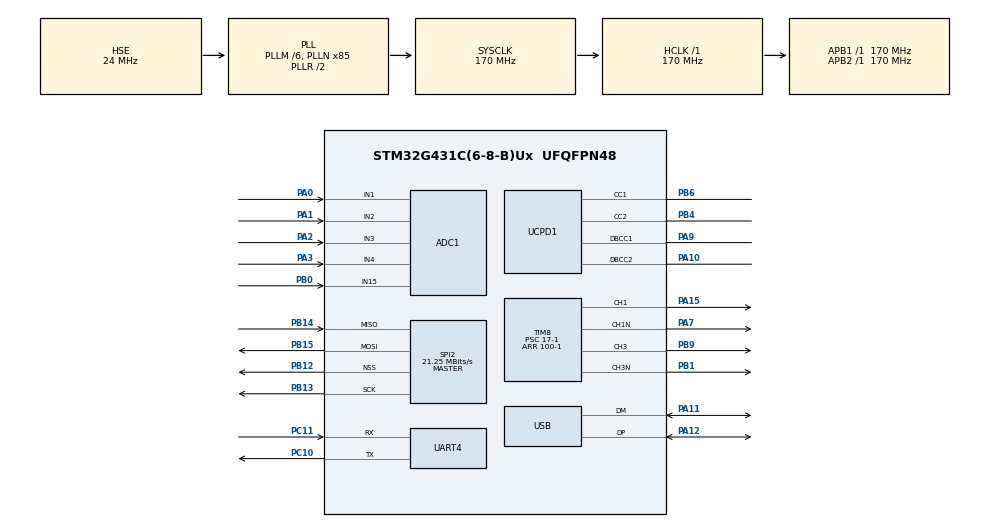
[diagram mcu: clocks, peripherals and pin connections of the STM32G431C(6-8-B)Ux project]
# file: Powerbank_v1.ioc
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ADC1.Channel-0\#ChannelRegularConversion=ADC_CHANNEL_1
ADC1.Channel-1\#ChannelRegularConversion=ADC_CHANNEL_2
ADC1.Channel-2\#ChannelRegularConversion=ADC_CHANNEL_3
ADC1.Channel-3\#ChannelRegularConversion=ADC_CHANNEL_4
ADC1.Channel-4\#ChannelRegularConversion=ADC_CHANNEL_15
ADC1.ContinuousConvMode=ENABLE
ADC1.DMAContinuousRequests=ENABLE
ADC1.DiscontinuousConvMode=DISABLE
ADC1.ExternalTrigConv=ADC_EXTERNALTRIG_T3_TRGO
ADC1.NbrOfConversion=5
ADC1.NbrOfConversionFlag=1
ADC1.OffsetNumber-0\#ChannelRegularConversion=ADC_OFFSET_NONE
ADC1.OffsetNumber-1\#ChannelRegularConversion=ADC_OFFSET_NONE
ADC1.OffsetNumber-2\#ChannelRegularConversion=ADC_OFFSET_NONE
ADC1.OffsetNumber-3\#ChannelRegularConversion=ADC_OFFSET_NONE
ADC1.OffsetNumber-4\#ChannelRegularConversion=ADC_OFFSET_NONE
ADC1.Overrun=ADC_OVR_DATA_OVERWRITTEN
ADC1.Rank-0\#ChannelRegularConversion=1
ADC1.Rank-1\#ChannelRegularConversion=2
ADC1.Rank-2\#ChannelRegularConversion=3
ADC1.Rank-3\#ChannelRegularConversion=4
ADC1.Rank-4\#ChannelRegularConversion=5
ADC1.SamplingTime-0\#ChannelRegularConversion=ADC_SAMPLETIME_640CYCLES_5
ADC1.SamplingTime-1\#ChannelRegularConversion=ADC_SAMPLETIME_640CYCLES_5
ADC1.SamplingTime-2\#ChannelRegularConversion=ADC_SAMPLETIME_640CYCLES_5
ADC1.SamplingTime-3\#ChannelRegularConversion=ADC_SAMPLETIME_640CYCLES_5
ADC1.SamplingTime-4\#ChannelRegularConversion=ADC_SAMPLETIME_640CYCLES_5
ADC1.master=1
Dma.ADC1.2.Direction=DMA_PERIPH_TO_MEMORY
Dma.ADC1.2.EventEnable=DISABLE
Dma.ADC1.2.Instance=DMA1_Channel3
Dma.ADC1.2.MemDataAlignment=DMA_MDATAALIGN_WORD
Dma.ADC1.2.MemInc=DMA_MINC_ENABLE
Dma.ADC1.2.Mode=DMA_CIRCULAR
Dma.ADC1.2.PeriphDataAlignment=DMA_PDATAALIGN_HALFWORD
Dma.ADC1.2.PeriphInc=DMA_PINC_DISABLE
Dma.ADC1.2.Polarity=HAL_DMAMUX_REQ_GEN_RISING
Dma.ADC1.2.Priority=DMA_PRIORITY_HIGH
Dma.ADC1.2.RequestNumber=1
Dma.ADC1.2.SignalID=NONE
Dma.ADC1.2.SyncEnable=DISABLE
Dma.ADC1.2.SyncPolarity=HAL_DMAMUX_SYNC_NO_EVENT
Dma.ADC1.2.SyncRequestNumber=1
Dma.ADC1.2.SyncSignalID=NONE
Dma.Request0=UCPD1_RX
Dma.Request1=UCPD1_TX
Dma.Request2=ADC1
Dma.UCPD1_RX.0.Direction=DMA_PERIPH_TO_MEMORY
Dma.UCPD1_RX.0.EventEnable=DISABLE
Dma.UCPD1_RX.0.Instance=DMA1_Channel1
Dma.UCPD1_RX.0.MemDataAlignment=DMA_MDATAALIGN_BYTE
Dma.UCPD1_RX.0.MemInc=DMA_MINC_ENABLE
Dma.UCPD1_RX.0.Mode=DMA_NORMAL
Dma.UCPD1_RX.0.PeriphDataAlignment=DMA_PDATAALIGN_BYTE
Dma.UCPD1_RX.0.PeriphInc=DMA_PINC_DISABLE
Dma.UCPD1_RX.0.Polarity=HAL_DMAMUX_REQ_GEN_RISING
Dma.UCPD1_RX.0.Priority=DMA_PRIORITY_LOW
Dma.UCPD1_RX.0.RequestNumber=1
Dma.UCPD1_RX.0.SignalID=NONE
Dma.UCPD1_RX.0.SyncEnable=DISABLE
Dma.UCPD1_RX.0.SyncPolarity=HAL_DMAMUX_SYNC_NO_EVENT
Dma.UCPD1_RX.0.SyncRequestNumber=1
Dma.UCPD1_RX.0.SyncSignalID=NONE
Dma.UCPD1_TX.1.Direction=DMA_MEMORY_TO_PERIPH
Dma.UCPD1_TX.1.EventEnable=DISABLE
Dma.UCPD1_TX.1.Instance=DMA1_Channel2
Dma.UCPD1_TX.1.MemDataAlignment=DMA_MDATAALIGN_BYTE
Dma.UCPD1_TX.1.MemInc=DMA_MINC_ENABLE
Dma.UCPD1_TX.1.Mode=DMA_NORMAL
Dma.UCPD1_TX.1.PeriphDataAlignment=DMA_PDATAALIGN_BYTE
Dma.UCPD1_TX.1.PeriphInc=DMA_PINC_DISABLE
Dma.UCPD1_TX.1.Polarity=HAL_DMAMUX_REQ_GEN_RISING
Dma.UCPD1_TX.1.Priority=DMA_PRIORITY_LOW
Dma.UCPD1_TX.1.RequestNumber=1
Dma.UCPD1_TX.1.SignalID=NONE
Dma.UCPD1_TX.1.SyncEnable=DISABLE
Dma.UCPD1_TX.1.SyncPolarity=HAL_DMAMUX_SYNC_NO_EVENT
Dma.UCPD1_TX.1.SyncRequestNumber=1
Dma.UCPD1_TX.1.SyncSignalID=NONE
FREERTOS.Tasks01=defaultTask,24,512,StartDefaultTask,Default,NULL,Dynamic,NULL,NULL
FREERTOS.configMINIMAL_STACK_SIZE=512
FREERTOS.configTOTAL_HEAP_SIZE=8000
FREERTOS.configUSE_NEWLIB_REENTRANT=1
Mcu.Family=STM32G4
Mcu.Name=STM32G431C(6-8-B)Ux
Mcu.Package=UFQFPN48
Mcu.UserConstants=VDDA_APPLI,3300
NVIC.DMA1_Channel1_IRQn=true\:5\:0\:false\:false\:true\:true\:false\:true\:true
NVIC.DMA1_Channel2_IRQn=true\:5\:0\:false\:false\:true\:true\:false\:true\:true
NVIC.DMA1_Channel3_IRQn=true\:5\:0\:false\:false\:true\:true\:false\:true\:true
NVIC.PriorityGroup=NVIC_PRIORITYGROUP_4
NVIC.TIM1_TRG_COM_TIM17_IRQn=true\:5\:0\:false\:false\:true\:false\:false\:true\:true
NVIC.TimeBase=TIM1_TRG_COM_TIM17_IRQn
NVIC.TimeBaseIP=TIM17
NVIC.UCPD1_IRQn=true\:5\:0\:false\:false\:true\:true\:true\:false\:true
NVIC.USB_LP_IRQn=true\:5\:0\:false\:false\:true\:true\:false\:true\:true
PA0.Mode=IN1-Single-Ended
PA0.Signal=ADC1_IN1
PA1.Mode=IN2-Single-Ended
PA1.Signal=ADC1_IN2
PA10.Mode=EnableDeadBattery
PA10.Signal=UCPD1_DBCC2
PA11.Mode=Device
PA11.Signal=USB_DM
PA12.Mode=Device
PA12.Signal=USB_DP
PA15.Signal=S_TIM8_CH1
PA2.Mode=IN3-Single-Ended
PA2.Signal=ADC1_IN3
PA3.Mode=IN4-Single-Ended
PA3.Signal=ADC1_IN4
PA7.Mode=PWM Generation1 CH1 CH1N
PA7.Signal=TIM8_CH1N
PA9.Mode=EnableDeadBattery
PA9.Signal=UCPD1_DBCC1
PB0.Mode=IN15-Single-Ended
PB0.Signal=ADC1_IN15
PB1.Mode=PWM Generation3 CH3 CH3N
PB1.Signal=TIM8_CH3N
PB12.Mode=NSS_Signal_Hard_Output
PB12.Signal=SPI2_NSS
PB13.Mode=Full_Duplex_Master
PB13.Signal=SPI2_SCK
PB14.Mode=Full_Duplex_Master
PB14.Signal=SPI2_MISO
PB15.Mode=Full_Duplex_Master
PB15.Signal=SPI2_MOSI
PB4.Mode=Dual_Role_AllSignals
PB4.Signal=UCPD1_CC2
PB6.Mode=Dual_Role_AllSignals
PB6.Signal=UCPD1_CC1
PB9.Signal=S_TIM8_CH3
PC10.Mode=Asynchronous
PC10.Signal=UART4_TX
PC11.Mode=Asynchronous
PC11.Signal=UART4_RX
PC14-OSC32_IN.Mode=LSE-External-Oscillator
PC14-OSC32_IN.Signal=RCC_OSC32_IN
PC15-OSC32_OUT.Mode=LSE-External-Oscillator
PC15-OSC32_OUT.Signal=RCC_OSC32_OUT
PF0-OSC_IN.Mode=HSE-External-Oscillator
PF0-OSC_IN.Signal=RCC_OSC_IN
PF1-OSC_OUT.Mode=HSE-External-Oscillator
PF1-OSC_OUT.Signal=RCC_OSC_OUT
ProjectManager.HeapSize=0x200
ProjectManager.StackSize=0x400
ProjectManager.TargetToolchain=STM32CubeIDE
RCC.ADC12Freq_Value=170000000
RCC.AHBFreq_Value=170000000
RCC.APB1Freq_Value=170000000
RCC.APB1TimFreq_Value=170000000
RCC.APB2Freq_Value=170000000
RCC.APB2TimFreq_Value=170000000
RCC.CK48CLockSelection=RCC_USBCLKSOURCE_HSI48
RCC.CortexFreq_Value=170000000
RCC.EXTERNAL_CLOCK_VALUE=12288000
RCC.HCLKFreq_Value=170000000
RCC.HSE_VALUE=24000000
RCC.HSI48_VALUE=48000000
RCC.HSI_VALUE=16000000
RCC.PLLM=RCC_PLLM_DIV6
RCC.PLLN=85
RCC.PLLSourceVirtual=RCC_PLLSOURCE_HSE
RCC.SYSCLKFreq_VALUE=170000000
RCC.SYSCLKSource=RCC_SYSCLKSOURCE_PLLCLK
RCC.USBFreq_Value=48000000
RCC.VCOOutputFreq_Value=340000000
SH.S_TIM8_CH1.0=TIM8_CH1,PWM Generation1 CH1 CH1N
SH.S_TIM8_CH3.0=TIM8_CH3,PWM Generation3 CH3 CH3N
SPI2.BaudRatePrescaler=SPI_BAUDRATEPRESCALER_8
SPI2.CalculateBaudRate=21.25 MBits/s
SPI2.Direction=SPI_DIRECTION_2LINES
SPI2.Mode=SPI_MODE_MASTER
SPI2.VirtualNSS=VM_NSSHARD
SPI2.VirtualType=VM_MASTER
TIM3.PeriodNoDither=100-1
TIM3.Prescaler=17-1
TIM3.TIM_MasterOutputTrigger=TIM_TRGO_UPDATE
TIM8.Channel-PWM\ Generation1\ CH1\ CH1N=TIM_CHANNEL_1
TIM8.Channel-PWM\ Generation3\ CH3\ CH3N=TIM_CHANNEL_3
TIM8.PeriodNoDither=100-1
TIM8.Prescaler=17-1
USB_DEVICE.CLASS_NAME_FS=CDC
USB_DEVICE.VirtualMode=Cdc
USB_DEVICE.VirtualModeFS=Cdc_FS
VP_FREERTOS_VS_CMSIS_V2.Mode=CMSIS_V2
VP_SYS_VS_DBSignals.Mode=DisableDeadBatterySignals
VP_SYS_VS_tim17.Mode=TIM17
VP_TIM3_VS_ClockSourceINT.Mode=Internal
VP_USB_DEVICE_VS_USB_DEVICE_CDC_FS.Mode=CDC_FS
board=custom

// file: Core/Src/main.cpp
/* USER CODE BEGIN Header */
/**
  ******************************************************************************
  * @file           : main.c
  * @brief          : Main program body
  ******************************************************************************
  * @attention
  *
  * Copyright (c) 2025 STMicroelectronics.
  * All rights reserved.
  *
  * This software is licensed under terms that can be found in the LICENSE file
  * in the root directory of this software component.
  * If no LICENSE file comes with this software, it is provided AS-IS.
  *
  ******************************************************************************
  */
/* USER CODE END Header */
#include "main.h"
#include "cmsis_os.h"
#include "usb_device.h"

/* USER CODE BEGIN Includes */
#include "Statemachine.h"

/* USER CODE END Includes */

ADC_HandleTypeDef hadc1;
DMA_HandleTypeDef hdma_adc1;

SPI_HandleTypeDef hspi2;

TIM_HandleTypeDef htim3;
TIM_HandleTypeDef htim8;

UART_HandleTypeDef huart4;

/* Definitions for defaultTask */
osThreadId_t defaultTaskHandle;
const osThreadAttr_t defaultTask_attributes = {
  .name = "defaultTask",
  .stack_size = 512 * 4,
  .priority = (osPriority_t) osPriorityNormal
};
/* USER CODE BEGIN PV */
//USBPD_StatusTypeDef status;

Statemachine statemachine(&huart4, &hadc1, &htim3, &htim8, &hspi2);

extern "C" void SystemClock_Config(void);
/* USER CODE END PV */

void SystemClock_Config(void);
static void MX_GPIO_Init(void);
static void MX_DMA_Init(void);
static void MX_UCPD1_Init(void);
static void MX_UART4_Init(void);
static void MX_TIM8_Init(void);
static void MX_ADC1_Init(void);
static void MX_TIM3_Init(void);
static void MX_SPI2_Init(void);
void StartDefaultTask(void *argument);

int main(void)
{

  /* MCU Configuration--------------------------------------------------------*/

  /* Reset of all peripherals, Initializes the Flash interface and the Systick. */
  HAL_Init();

  /* Configure the system clock */
  SystemClock_Config();

  /* Initialize all configured peripherals */
  MX_GPIO_Init();
  MX_DMA_Init();
  MX_UCPD1_Init();
  MX_UART4_Init();
  MX_TIM8_Init();
  MX_ADC1_Init();
  MX_TIM3_Init();
  MX_SPI2_Init();

  /* Init scheduler */
  osKernelInitialize();

  /* Create the thread(s) */
  /* creation of defaultTask */
  defaultTaskHandle = osThreadNew(StartDefaultTask, NULL, &defaultTask_attributes);

  /* Start scheduler */
  osKernelStart();

  /* We should never get here as control is now taken by the scheduler */

  /* Infinite loop */
  while (1)
  {

  }
}

void SystemClock_Config(void)
{
  RCC_OscInitTypeDef RCC_OscInitStruct = {0};
  RCC_ClkInitTypeDef RCC_ClkInitStruct = {0};

  /** Configure the main internal regulator output voltage
  */
  HAL_PWREx_ControlVoltageScaling(PWR_REGULATOR_VOLTAGE_SCALE1_BOOST);

  /** Initializes the RCC Oscillators according to the specified parameters
  * in the RCC_OscInitTypeDef structure.
  */
  RCC_OscInitStruct.OscillatorType = RCC_OSCILLATORTYPE_HSI|RCC_OSCILLATORTYPE_HSI48
                              |RCC_OSCILLATORTYPE_HSE;
  RCC_OscInitStruct.HSEState = RCC_HSE_ON;
  RCC_OscInitStruct.HSIState = RCC_HSI_ON;
  RCC_OscInitStruct.HSICalibrationValue = RCC_HSICALIBRATION_DEFAULT;
  RCC_OscInitStruct.HSI48State = RCC_HSI48_ON;
  RCC_OscInitStruct.PLL.PLLState = RCC_PLL_ON;
  RCC_OscInitStruct.PLL.PLLSource = RCC_PLLSOURCE_HSE;
  RCC_OscInitStruct.PLL.PLLM = RCC_PLLM_DIV6;
  RCC_OscInitStruct.PLL.PLLN = 85;
  RCC_OscInitStruct.PLL.PLLP = RCC_PLLP_DIV2;
  RCC_OscInitStruct.PLL.PLLQ = RCC_PLLQ_DIV2;
  RCC_OscInitStruct.PLL.PLLR = RCC_PLLR_DIV2;
  if (HAL_RCC_OscConfig(&RCC_OscInitStruct) != HAL_OK)
  {
    Error_Handler();
  }

  /** Initializes the CPU, AHB and APB buses clocks
  */
  RCC_ClkInitStruct.ClockType = RCC_CLOCKTYPE_HCLK|RCC_CLOCKTYPE_SYSCLK
                              |RCC_CLOCKTYPE_PCLK1|RCC_CLOCKTYPE_PCLK2;
  RCC_ClkInitStruct.SYSCLKSource = RCC_SYSCLKSOURCE_PLLCLK;
  RCC_ClkInitStruct.AHBCLKDivider = RCC_SYSCLK_DIV1;
  RCC_ClkInitStruct.APB1CLKDivider = RCC_HCLK_DIV1;
  RCC_ClkInitStruct.APB2CLKDivider = RCC_HCLK_DIV1;

  if (HAL_RCC_ClockConfig(&RCC_ClkInitStruct, FLASH_LATENCY_4) != HAL_OK)
  {
    Error_Handler();
  }
}

static void MX_ADC1_Init(void)
{

  ADC_MultiModeTypeDef multimode = {0};
  ADC_ChannelConfTypeDef sConfig = {0};

  /** Common config
  */
  hadc1.Instance = ADC1;
  hadc1.Init.ClockPrescaler = ADC_CLOCK_SYNC_PCLK_DIV4;
  hadc1.Init.Resolution = ADC_RESOLUTION_12B;
  hadc1.Init.DataAlign = ADC_DATAALIGN_RIGHT;
  hadc1.Init.GainCompensation = 0;
  hadc1.Init.ScanConvMode = ADC_SCAN_ENABLE;
  hadc1.Init.EOCSelection = ADC_EOC_SINGLE_CONV;
  hadc1.Init.LowPowerAutoWait = DISABLE;
  hadc1.Init.ContinuousConvMode = ENABLE;
  hadc1.Init.NbrOfConversion = 5;
  hadc1.Init.DiscontinuousConvMode = DISABLE;
  hadc1.Init.ExternalTrigConv = ADC_EXTERNALTRIG_T3_TRGO;
  hadc1.Init.ExternalTrigConvEdge = ADC_EXTERNALTRIGCONVEDGE_RISING;
  hadc1.Init.DMAContinuousRequests = ENABLE;
  hadc1.Init.Overrun = ADC_OVR_DATA_OVERWRITTEN;
  hadc1.Init.OversamplingMode = DISABLE;
  if (HAL_ADC_Init(&hadc1) != HAL_OK)
  {
    Error_Handler();
  }

  /** Configure the ADC multi-mode
  */
  multimode.Mode = ADC_MODE_INDEPENDENT;
  if (HAL_ADCEx_MultiModeConfigChannel(&hadc1, &multimode) != HAL_OK)
  {
    Error_Handler();
  }

  /** Configure Regular Channel
  */
  sConfig.Channel = ADC_CHANNEL_1;
  sConfig.Rank = ADC_REGULAR_RANK_1;
  sConfig.SamplingTime = ADC_SAMPLETIME_640CYCLES_5;
  sConfig.SingleDiff = ADC_SINGLE_ENDED;
  sConfig.OffsetNumber = ADC_OFFSET_NONE;
  sConfig.Offset = 0;
  if (HAL_ADC_ConfigChannel(&hadc1, &sConfig) != HAL_OK)
  {
    Error_Handler();
  }

  /** Configure Regular Channel
  */
  sConfig.Channel = ADC_CHANNEL_2;
  sConfig.Rank = ADC_REGULAR_RANK_2;
  if (HAL_ADC_ConfigChannel(&hadc1, &sConfig) != HAL_OK)
  {
    Error_Handler();
  }

  /** Configure Regular Channel
  */
  sConfig.Channel = ADC_CHANNEL_3;
  sConfig.Rank = ADC_REGULAR_RANK_3;
  if (HAL_ADC_ConfigChannel(&hadc1, &sConfig) != HAL_OK)
  {
    Error_Handler();
  }

  /** Configure Regular Channel
  */
  sConfig.Channel = ADC_CHANNEL_4;
  sConfig.Rank = ADC_REGULAR_RANK_4;
  if (HAL_ADC_ConfigChannel(&hadc1, &sConfig) != HAL_OK)
  {
    Error_Handler();
  }

  /** Configure Regular Channel
  */
  sConfig.Channel = ADC_CHANNEL_15;
  sConfig.Rank = ADC_REGULAR_RANK_5;
  if (HAL_ADC_ConfigChannel(&hadc1, &sConfig) != HAL_OK)
  {
    Error_Handler();
  }

}

static void MX_SPI2_Init(void)
{

  /* SPI2 parameter configuration*/
  hspi2.Instance = SPI2;
  hspi2.Init.Mode = SPI_MODE_MASTER;
  hspi2.Init.Direction = SPI_DIRECTION_2LINES;
  hspi2.Init.DataSize = SPI_DATASIZE_4BIT;
  hspi2.Init.CLKPolarity = SPI_POLARITY_LOW;
  hspi2.Init.CLKPhase = SPI_PHASE_1EDGE;
  hspi2.Init.NSS = SPI_NSS_HARD_OUTPUT;
  hspi2.Init.BaudRatePrescaler = SPI_BAUDRATEPRESCALER_8;
  hspi2.Init.FirstBit = SPI_FIRSTBIT_MSB;
  hspi2.Init.TIMode = SPI_TIMODE_DISABLE;
  hspi2.Init.CRCCalculation = SPI_CRCCALCULATION_DISABLE;
  hspi2.Init.CRCPolynomial = 7;
  hspi2.Init.CRCLength = SPI_CRC_LENGTH_DATASIZE;
  hspi2.Init.NSSPMode = SPI_NSS_PULSE_ENABLE;
  if (HAL_SPI_Init(&hspi2) != HAL_OK)
  {
    Error_Handler();
  }

}

static void MX_TIM3_Init(void)
{

  TIM_ClockConfigTypeDef sClockSourceConfig = {0};
  TIM_MasterConfigTypeDef sMasterConfig = {0};

  htim3.Instance = TIM3;
  htim3.Init.Prescaler = 17-1;
  htim3.Init.CounterMode = TIM_COUNTERMODE_UP;
  htim3.Init.Period = 99;
  htim3.Init.ClockDivision = TIM_CLOCKDIVISION_DIV1;
  htim3.Init.AutoReloadPreload = TIM_AUTORELOAD_PRELOAD_DISABLE;
  if (HAL_TIM_Base_Init(&htim3) != HAL_OK)
  {
    Error_Handler();
  }
  sClockSourceConfig.ClockSource = TIM_CLOCKSOURCE_INTERNAL;
  if (HAL_TIM_ConfigClockSource(&htim3, &sClockSourceConfig) != HAL_OK)
  {
    Error_Handler();
  }
  sMasterConfig.MasterOutputTrigger = TIM_TRGO_UPDATE;
  sMasterConfig.MasterSlaveMode = TIM_MASTERSLAVEMODE_DISABLE;
  if (HAL_TIMEx_MasterConfigSynchronization(&htim3, &sMasterConfig) != HAL_OK)
  {
    Error_Handler();
  }

}

static void MX_TIM8_Init(void)
{

  TIM_MasterConfigTypeDef sMasterConfig = {0};
  TIM_OC_InitTypeDef sConfigOC = {0};
  TIM_BreakDeadTimeConfigTypeDef sBreakDeadTimeConfig = {0};

  htim8.Instance = TIM8;
  htim8.Init.Prescaler = 17-1;
  htim8.Init.CounterMode = TIM_COUNTERMODE_UP;
  htim8.Init.Period = 99;
  htim8.Init.ClockDivision = TIM_CLOCKDIVISION_DIV1;
  htim8.Init.RepetitionCounter = 0;
  htim8.Init.AutoReloadPreload = TIM_AUTORELOAD_PRELOAD_DISABLE;
  if (HAL_TIM_PWM_Init(&htim8) != HAL_OK)
  {
    Error_Handler();
  }
  sMasterConfig.MasterOutputTrigger = TIM_TRGO_RESET;
  sMasterConfig.MasterOutputTrigger2 = TIM_TRGO2_RESET;
  sMasterConfig.MasterSlaveMode = TIM_MASTERSLAVEMODE_DISABLE;
  if (HAL_TIMEx_MasterConfigSynchronization(&htim8, &sMasterConfig) != HAL_OK)
  {
    Error_Handler();
  }
  sConfigOC.OCMode = TIM_OCMODE_PWM1;
  sConfigOC.Pulse = 0;
  sConfigOC.OCPolarity = TIM_OCPOLARITY_HIGH;
  sConfigOC.OCNPolarity = TIM_OCNPOLARITY_HIGH;
  sConfigOC.OCFastMode = TIM_OCFAST_DISABLE;
  sConfigOC.OCIdleState = TIM_OCIDLESTATE_RESET;
  sConfigOC.OCNIdleState = TIM_OCNIDLESTATE_RESET;
  if (HAL_TIM_PWM_ConfigChannel(&htim8, &sConfigOC, TIM_CHANNEL_1) != HAL_OK)
  {
    Error_Handler();
  }
  if (HAL_TIM_PWM_ConfigChannel(&htim8, &sConfigOC, TIM_CHANNEL_3) != HAL_OK)
  {
    Error_Handler();
  }
  sBreakDeadTimeConfig.OffStateRunMode = TIM_OSSR_DISABLE;
  sBreakDeadTimeConfig.OffStateIDLEMode = TIM_OSSI_DISABLE;
  sBreakDeadTimeConfig.LockLevel = TIM_LOCKLEVEL_OFF;
  sBreakDeadTimeConfig.DeadTime = 0;
  sBreakDeadTimeConfig.BreakState = TIM_BREAK_DISABLE;
  sBreakDeadTimeConfig.BreakPolarity = TIM_BREAKPOLARITY_HIGH;
  sBreakDeadTimeConfig.BreakFilter = 0;
  sBreakDeadTimeConfig.BreakAFMode = TIM_BREAK_AFMODE_INPUT;
  sBreakDeadTimeConfig.Break2State = TIM_BREAK2_DISABLE;
  sBreakDeadTimeConfig.Break2Polarity = TIM_BREAK2POLARITY_HIGH;
  sBreakDeadTimeConfig.Break2Filter = 0;
  sBreakDeadTimeConfig.Break2AFMode = TIM_BREAK_AFMODE_INPUT;
  sBreakDeadTimeConfig.AutomaticOutput = TIM_AUTOMATICOUTPUT_DISABLE;
  if (HAL_TIMEx_ConfigBreakDeadTime(&htim8, &sBreakDeadTimeConfig) != HAL_OK)
  {
    Error_Handler();
  }
  HAL_TIM_MspPostInit(&htim8);

}

static void MX_UART4_Init(void)
{

  huart4.Instance = UART4;
  huart4.Init.BaudRate = 115200;
  huart4.Init.WordLength = UART_WORDLENGTH_8B;
  huart4.Init.StopBits = UART_STOPBITS_1;
  huart4.Init.Parity = UART_PARITY_NONE;
  huart4.Init.Mode = UART_MODE_TX_RX;
  huart4.Init.HwFlowCtl = UART_HWCONTROL_NONE;
  huart4.Init.OverSampling = UART_OVERSAMPLING_16;
  huart4.Init.OneBitSampling = UART_ONE_BIT_SAMPLE_DISABLE;
  huart4.Init.ClockPrescaler = UART_PRESCALER_DIV1;
  huart4.AdvancedInit.AdvFeatureInit = UART_ADVFEATURE_NO_INIT;
  if (HAL_UART_Init(&huart4) != HAL_OK)
  {
    Error_Handler();
  }
  if (HAL_UARTEx_SetTxFifoThreshold(&huart4, UART_TXFIFO_THRESHOLD_1_8) != HAL_OK)
  {
    Error_Handler();
  }
  if (HAL_UARTEx_SetRxFifoThreshold(&huart4, UART_RXFIFO_THRESHOLD_1_8) != HAL_OK)
  {
    Error_Handler();
  }
  if (HAL_UARTEx_DisableFifoMode(&huart4) != HAL_OK)
  {
    Error_Handler();
  }

}

static void MX_UCPD1_Init(void)
{

  /* USER CODE BEGIN UCPD1_Init 0 */
////
  /* USER CODE END UCPD1_Init 0 */

  LL_GPIO_InitTypeDef GPIO_InitStruct = {0};

  /* Peripheral clock enable */
  LL_APB1_GRP2_EnableClock(LL_APB1_GRP2_PERIPH_UCPD1);

  LL_AHB2_GRP1_EnableClock(LL_AHB2_GRP1_PERIPH_GPIOB);
  /**UCPD1 GPIO Configuration
  PB4   ------> UCPD1_CC2
  PB6   ------> UCPD1_CC1
  */
  GPIO_InitStruct.Pin = LL_GPIO_PIN_4;
  GPIO_InitStruct.Mode = LL_GPIO_MODE_ANALOG;
  GPIO_InitStruct.Pull = LL_GPIO_PULL_NO;
  LL_GPIO_Init(GPIOB, &GPIO_InitStruct);

  GPIO_InitStruct.Pin = LL_GPIO_PIN_6;
  GPIO_InitStruct.Mode = LL_GPIO_MODE_ANALOG;
  GPIO_InitStruct.Pull = LL_GPIO_PULL_NO;
  LL_GPIO_Init(GPIOB, &GPIO_InitStruct);

  /* UCPD1 DMA Init */

  /* UCPD1_RX Init */
  LL_DMA_SetPeriphRequest(DMA1, LL_DMA_CHANNEL_1, LL_DMAMUX_REQ_UCPD1_RX);

  LL_DMA_SetDataTransferDirection(DMA1, LL_DMA_CHANNEL_1, LL_DMA_DIRECTION_PERIPH_TO_MEMORY);

  LL_DMA_SetChannelPriorityLevel(DMA1, LL_DMA_CHANNEL_1, LL_DMA_PRIORITY_LOW);

  LL_DMA_SetMode(DMA1, LL_DMA_CHANNEL_1, LL_DMA_MODE_NORMAL);

  LL_DMA_SetPeriphIncMode(DMA1, LL_DMA_CHANNEL_1, LL_DMA_PERIPH_NOINCREMENT);

  LL_DMA_SetMemoryIncMode(DMA1, LL_DMA_CHANNEL_1, LL_DMA_MEMORY_INCREMENT);

  LL_DMA_SetPeriphSize(DMA1, LL_DMA_CHANNEL_1, LL_DMA_PDATAALIGN_BYTE);

  LL_DMA_SetMemorySize(DMA1, LL_DMA_CHANNEL_1, LL_DMA_MDATAALIGN_BYTE);

  /* UCPD1_TX Init */
  LL_DMA_SetPeriphRequest(DMA1, LL_DMA_CHANNEL_2, LL_DMAMUX_REQ_UCPD1_TX);

  LL_DMA_SetDataTransferDirection(DMA1, LL_DMA_CHANNEL_2, LL_DMA_DIRECTION_MEMORY_TO_PERIPH);

  LL_DMA_SetChannelPriorityLevel(DMA1, LL_DMA_CHANNEL_2, LL_DMA_PRIORITY_LOW);

  LL_DMA_SetMode(DMA1, LL_DMA_CHANNEL_2, LL_DMA_MODE_NORMAL);

  LL_DMA_SetPeriphIncMode(DMA1, LL_DMA_CHANNEL_2, LL_DMA_PERIPH_NOINCREMENT);

  LL_DMA_SetMemoryIncMode(DMA1, LL_DMA_CHANNEL_2, LL_DMA_MEMORY_INCREMENT);

  LL_DMA_SetPeriphSize(DMA1, LL_DMA_CHANNEL_2, LL_DMA_PDATAALIGN_BYTE);

  LL_DMA_SetMemorySize(DMA1, LL_DMA_CHANNEL_2, LL_DMA_MDATAALIGN_BYTE);

  /* UCPD1 interrupt Init */
  NVIC_SetPriority(UCPD1_IRQn, NVIC_EncodePriority(NVIC_GetPriorityGrouping(),5, 0));
  NVIC_EnableIRQ(UCPD1_IRQn);

  /* USER CODE BEGIN UCPD1_Init 1 */
////
  /* USER CODE END UCPD1_Init 1 */
  /* USER CODE BEGIN UCPD1_Init 2 */
////
  /* USER CODE END UCPD1_Init 2 */

}

static void MX_DMA_Init(void)
{

  /* DMA controller clock enable */
  __HAL_RCC_DMAMUX1_CLK_ENABLE();
  __HAL_RCC_DMA1_CLK_ENABLE();

  /* DMA interrupt init */
  /* DMA1_Channel1_IRQn interrupt configuration */
  NVIC_SetPriority(DMA1_Channel1_IRQn, NVIC_EncodePriority(NVIC_GetPriorityGrouping(),5, 0));
  NVIC_EnableIRQ(DMA1_Channel1_IRQn);
  /* DMA1_Channel2_IRQn interrupt configuration */
  NVIC_SetPriority(DMA1_Channel2_IRQn, NVIC_EncodePriority(NVIC_GetPriorityGrouping(),5, 0));
  NVIC_EnableIRQ(DMA1_Channel2_IRQn);
  /* DMA1_Channel3_IRQn interrupt configuration */
  HAL_NVIC_SetPriority(DMA1_Channel3_IRQn, 5, 0);
  HAL_NVIC_EnableIRQ(DMA1_Channel3_IRQn);

}

static void MX_GPIO_Init(void)
{

  /* GPIO Ports Clock Enable */
  __HAL_RCC_GPIOC_CLK_ENABLE();
  __HAL_RCC_GPIOF_CLK_ENABLE();
  __HAL_RCC_GPIOA_CLK_ENABLE();
  __HAL_RCC_GPIOB_CLK_ENABLE();

  /* USER CODE BEGIN MX_GPIO_Init_2 */
  __HAL_RCC_HSI48_ENABLE();
  __HAL_RCC_CRS_CLK_ENABLE();
  /* USER CODE END MX_GPIO_Init_2 */
}

/* USER CODE BEGIN 4 */

// Callback function that runs when the ADC buffer is 50% filled
void HAL_ADC_ConvHalfCpltCallback(ADC_HandleTypeDef* hadc) {
//	stateMachine.adcHalfComplete(hadc);
}

// Callback function that runs when the ADC buffer is filled
void HAL_ADC_ConvCpltCallback(ADC_HandleTypeDef* hadc) {
	statemachine.adcComplete(hadc);
}

/* USER CODE END 4 */

void StartDefaultTask(void *argument)
{
  /* init code for USB_Device */
  MX_USB_Device_Init();
  /* USER CODE BEGIN 5 */
	statemachine.init();
  /* Infinite loop */
  for(;;)
  {
    osDelay(1);
    statemachine.iteration();
  }
  /* USER CODE END 5 */
}

void HAL_TIM_PeriodElapsedCallback(TIM_HandleTypeDef *htim)
{
  if (htim->Instance == TIM17)
  {
    HAL_IncTick();
  }
}

void Error_Handler(void)
{
  __disable_irq();
  while (1)
  {
  }
}
